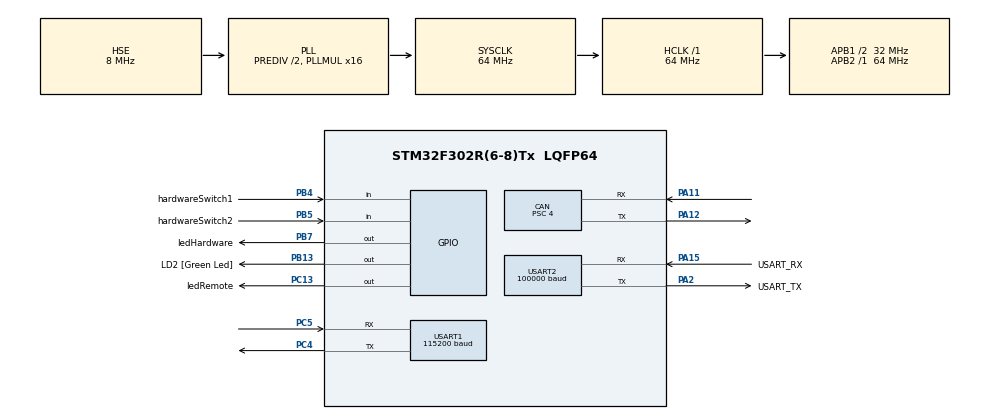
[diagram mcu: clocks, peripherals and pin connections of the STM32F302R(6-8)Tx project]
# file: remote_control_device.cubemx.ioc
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CAN.ABOM=ENABLE
CAN.AWUM=ENABLE
CAN.BS1=CAN_BS1_13TQ
CAN.BS2=CAN_BS2_2TQ
CAN.CalculateBaudRate=500000
CAN.CalculateTimeBit=2000.00
CAN.CalculateTimeQuantum=125.0
CAN.NART=ENABLE
CAN.Prescaler=4
CAN.SJW=CAN_SJW_1TQ
CAN.TXFP=ENABLE
Dma.Request0=USART1_TX
Dma.Request1=USART1_RX
Dma.Request2=USART2_RX
Dma.USART1_RX.1.Direction=DMA_PERIPH_TO_MEMORY
Dma.USART1_RX.1.Instance=DMA1_Channel5
Dma.USART1_RX.1.MemDataAlignment=DMA_MDATAALIGN_BYTE
Dma.USART1_RX.1.MemInc=DMA_MINC_ENABLE
Dma.USART1_RX.1.Mode=DMA_NORMAL
Dma.USART1_RX.1.PeriphDataAlignment=DMA_PDATAALIGN_BYTE
Dma.USART1_RX.1.PeriphInc=DMA_PINC_DISABLE
Dma.USART1_RX.1.Priority=DMA_PRIORITY_LOW
Dma.USART1_TX.0.Direction=DMA_MEMORY_TO_PERIPH
Dma.USART1_TX.0.Instance=DMA1_Channel4
Dma.USART1_TX.0.MemDataAlignment=DMA_MDATAALIGN_BYTE
Dma.USART1_TX.0.MemInc=DMA_MINC_ENABLE
Dma.USART1_TX.0.Mode=DMA_NORMAL
Dma.USART1_TX.0.PeriphDataAlignment=DMA_PDATAALIGN_BYTE
Dma.USART1_TX.0.PeriphInc=DMA_PINC_DISABLE
Dma.USART1_TX.0.Priority=DMA_PRIORITY_LOW
Dma.USART2_RX.2.Direction=DMA_PERIPH_TO_MEMORY
Dma.USART2_RX.2.Instance=DMA1_Channel6
Dma.USART2_RX.2.MemDataAlignment=DMA_MDATAALIGN_BYTE
Dma.USART2_RX.2.MemInc=DMA_MINC_ENABLE
Dma.USART2_RX.2.Mode=DMA_NORMAL
Dma.USART2_RX.2.PeriphDataAlignment=DMA_PDATAALIGN_BYTE
Dma.USART2_RX.2.PeriphInc=DMA_PINC_DISABLE
Dma.USART2_RX.2.Priority=DMA_PRIORITY_MEDIUM
FREERTOS.HEAP_NUMBER=1
FREERTOS.Tasks01=Application,24,250,startApplication,As weak,NULL,Dynamic,NULL,NULL
FREERTOS.configCHECK_FOR_STACK_OVERFLOW=2
FREERTOS.configRECORD_STACK_HIGH_ADDRESS=1
FREERTOS.configTIMER_QUEUE_LENGTH=3
FREERTOS.configTIMER_TASK_STACK_DEPTH=160
FREERTOS.configTOTAL_HEAP_SIZE=8350
IWDG.Reload=600
IWDG.Window=500
Mcu.Family=STM32F3
Mcu.Name=STM32F302R(6-8)Tx
Mcu.Package=LQFP64
NVIC.CAN_RX1_IRQn=true\:13\:0\:true\:true\:true\:3\:false\:true\:true
NVIC.CAN_SCE_IRQn=true\:13\:0\:true\:false\:true\:false\:true\:true
NVIC.DMA1_Channel4_IRQn=true\:15\:0\:true\:false\:true\:false\:false\:true
NVIC.DMA1_Channel5_IRQn=true\:15\:0\:true\:false\:true\:false\:false\:true
NVIC.DMA1_Channel6_IRQn=true\:15\:0\:true\:false\:true\:false\:false\:true
NVIC.PriorityGroup=NVIC_PRIORITYGROUP_4
NVIC.TIM1_UP_TIM16_IRQn=true\:0\:0\:false\:false\:true\:false\:false\:true
NVIC.TIM6_DAC_IRQn=true\:15\:0\:true\:false\:true\:false\:true\:true
NVIC.TimeBase=TIM1_UP_TIM16_IRQn
NVIC.TimeBaseIP=TIM1
NVIC.USART1_IRQn=true\:15\:0\:true\:false\:true\:false\:true\:true
NVIC.USART2_IRQn=true\:14\:0\:true\:false\:true\:false\:true\:true
NVIC.USB_HP_CAN_TX_IRQn=true\:13\:0\:true\:true\:true\:1\:false\:true\:true
NVIC.USB_LP_CAN_RX0_IRQn=true\:13\:0\:true\:true\:true\:2\:false\:true\:true
PA11.Mode=CAN_Activate
PA11.Signal=CAN_RX
PA12.Mode=CAN_Activate
PA12.Signal=CAN_TX
PA13.GPIO_Label=TMS
PA13.Mode=Trace_Asynchronous_SW
PA13.Signal=SYS_JTMS-SWDIO
PA14.GPIO_Label=TCK
PA14.Mode=Trace_Asynchronous_SW
PA14.Signal=SYS_JTCK-SWCLK
PA15.GPIO_Label=USART_RX
PA15.GPIO_PuPd=GPIO_NOPULL
PA15.GPIO_Speed=GPIO_SPEED_FREQ_LOW
PA15.Mode=Asynchronous
PA15.Signal=USART2_RX
PA2.GPIO_Label=USART_TX
PA2.GPIO_Mode=GPIO_MODE_AF_PP
PA2.GPIO_PuPd=GPIO_NOPULL
PA2.GPIO_Speed=GPIO_SPEED_FREQ_LOW
PA2.Mode=Asynchronous
PA2.Signal=USART2_TX
PB13.GPIO_Label=LD2 [Green Led]
PB13.Signal=GPIO_Output
PB3.GPIO_Label=SWO
PB3.Mode=Trace_Asynchronous_SW
PB3.Signal=SYS_JTDO-TRACESWO
PB4.GPIO_Label=hardwareSwitch1
PB4.GPIO_PuPd=GPIO_PULLUP
PB4.Signal=GPIO_Input
PB5.GPIO_Label=hardwareSwitch2
PB5.GPIO_PuPd=GPIO_PULLUP
PB5.Signal=GPIO_Input
PB7.GPIO_Label=ledHardware
PB7.Signal=GPIO_Output
PC13.GPIO_Label=ledRemote
PC13.Signal=GPIO_Output
PC14\ -\ OSC32_IN.Signal=RCC_OSC32_IN
PC15\ -\ OSC32_OUT.Signal=RCC_OSC32_OUT
PC4.Mode=Asynchronous
PC4.Signal=USART1_TX
PC5.Mode=Asynchronous
PC5.Signal=USART1_RX
PF0-OSC_IN.Mode=HSE-External-Clock-Source
PF0-OSC_IN.Signal=RCC_OSC_IN
PF1-OSC_OUT.Signal=RCC_OSC_OUT
ProjectManager.HeapSize=0x200
ProjectManager.StackSize=0x400
ProjectManager.TargetToolchain=Makefile
RCC.AHBFreq_Value=64000000
RCC.APB1CLKDivider=RCC_HCLK_DIV2
RCC.APB1Freq_Value=32000000
RCC.APB1TimFreq_Value=64000000
RCC.APB2Freq_Value=64000000
RCC.APB2TimFreq_Value=64000000
RCC.CortexFreq_Value=64000000
RCC.EnbaleCSS=true
RCC.HCLKFreq_Value=64000000
RCC.HSE_VALUE=8000000
RCC.HSI_VALUE=8000000
RCC.LSE_VALUE=32768
RCC.PLLM=8
RCC.PLLMUL=RCC_PLL_MUL16
RCC.PLLN=336
RCC.PLLP=RCC_PLLP_DIV4
RCC.PLLQ=7
RCC.PLLSourceVirtual=RCC_PLLSOURCE_HSE
RCC.RCC_PLLsource_Clock_Source_FROM_HSE=RCC_HSE_PREDIV_DIV2
RCC.SYSCLKFreq_VALUE=64000000
RCC.SYSCLKSourceVirtual=RCC_SYSCLKSOURCE_PLLCLK
RCC.USBFreq_Value=64000000
TIM6.Prescaler=15
USART1.BaudRate=115200
USART1.VirtualMode-Asynchronous=VM_ASYNC
USART2.BaudRate=100000
USART2.Mode=MODE_RX
USART2.Parity=PARITY_EVEN
USART2.StopBits=STOPBITS_2
USART2.SwapParam=ADVFEATURE_SWAP_DISABLE
USART2.VirtualMode-Asynchronous=VM_ASYNC
USART2.WordLength=WORDLENGTH_9B
VP_FREERTOS_VS_CMSIS_V2.Mode=CMSIS_V2
VP_IWDG_VS_IWDG.Mode=IWDG_Activate
VP_SYS_VS_tim1.Mode=TIM1
VP_TIM6_VS_ClockSourceINT.Mode=Enable_Timer
board=NUCLEO-F302R8

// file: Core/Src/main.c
/* USER CODE BEGIN Header */
/**
  ******************************************************************************
  * @file           : main.c
  * @brief          : Main program body
  ******************************************************************************
  * @attention
  *
  * <h2><center>&copy; Copyright (c) 2020 STMicroelectronics.
  * All rights reserved.</center></h2>
  *
  * This software component is licensed by ST under Ultimate Liberty license
  * SLA0044, the "License"; You may not use this file except in compliance with
  * the License. You may obtain a copy of the License at:
  *                             www.st.com/SLA0044
  *
  ******************************************************************************
  */
/* USER CODE END Header */
#include "main.h"
#include "cmsis_os.h"
#include "can.h"
#include "dma.h"
#include "iwdg.h"
#include "tim.h"
#include "usart.h"
#include "gpio.h"

void SystemClock_Config(void);
void MX_FREERTOS_Init(void);
static void MX_NVIC_Init(void);

int main(void)
{

  /* MCU Configuration--------------------------------------------------------*/

  /* Reset of all peripherals, Initializes the Flash interface and the Systick. */
  HAL_Init();

  /* Configure the system clock */
  SystemClock_Config();

  /* Initialize all configured peripherals */
  MX_GPIO_Init();
  MX_DMA_Init();
  MX_CAN_Init();
  MX_USART1_UART_Init();
  MX_USART2_UART_Init();
  MX_TIM6_Init();
  MX_IWDG_Init();

  /* Initialize interrupts */
  MX_NVIC_Init();

  /* Init scheduler */
  osKernelInitialize();  /* Call init function for freertos objects (in freertos.c) */
  MX_FREERTOS_Init();
  /* Start scheduler */
  osKernelStart();

  /* We should never get here as control is now taken by the scheduler */
  /* Infinite loop */
  while (1)
  {

  }
}

void SystemClock_Config(void)
{
  RCC_OscInitTypeDef RCC_OscInitStruct = {0};
  RCC_ClkInitTypeDef RCC_ClkInitStruct = {0};
  RCC_PeriphCLKInitTypeDef PeriphClkInit = {0};

  /** Initializes the RCC Oscillators according to the specified parameters
  * in the RCC_OscInitTypeDef structure.
  */
  RCC_OscInitStruct.OscillatorType = RCC_OSCILLATORTYPE_LSI|RCC_OSCILLATORTYPE_HSE;
  RCC_OscInitStruct.HSEState = RCC_HSE_BYPASS;
  RCC_OscInitStruct.HSEPredivValue = RCC_HSE_PREDIV_DIV2;
  RCC_OscInitStruct.HSIState = RCC_HSI_ON;
  RCC_OscInitStruct.LSIState = RCC_LSI_ON;
  RCC_OscInitStruct.PLL.PLLState = RCC_PLL_ON;
  RCC_OscInitStruct.PLL.PLLSource = RCC_PLLSOURCE_HSE;
  RCC_OscInitStruct.PLL.PLLMUL = RCC_PLL_MUL16;
  if (HAL_RCC_OscConfig(&RCC_OscInitStruct) != HAL_OK)
  {
    Error_Handler();
  }
  /** Initializes the CPU, AHB and APB buses clocks
  */
  RCC_ClkInitStruct.ClockType = RCC_CLOCKTYPE_HCLK|RCC_CLOCKTYPE_SYSCLK
                              |RCC_CLOCKTYPE_PCLK1|RCC_CLOCKTYPE_PCLK2;
  RCC_ClkInitStruct.SYSCLKSource = RCC_SYSCLKSOURCE_PLLCLK;
  RCC_ClkInitStruct.AHBCLKDivider = RCC_SYSCLK_DIV1;
  RCC_ClkInitStruct.APB1CLKDivider = RCC_HCLK_DIV2;
  RCC_ClkInitStruct.APB2CLKDivider = RCC_HCLK_DIV1;

  if (HAL_RCC_ClockConfig(&RCC_ClkInitStruct, FLASH_LATENCY_2) != HAL_OK)
  {
    Error_Handler();
  }
  PeriphClkInit.PeriphClockSelection = RCC_PERIPHCLK_USART1;
  PeriphClkInit.Usart1ClockSelection = RCC_USART1CLKSOURCE_PCLK1;
  if (HAL_RCCEx_PeriphCLKConfig(&PeriphClkInit) != HAL_OK)
  {
    Error_Handler();
  }
  /** Enables the Clock Security System
  */
  HAL_RCC_EnableCSS();
}

/**
  * @brief NVIC Configuration.
  * @retval None
  */
static void MX_NVIC_Init(void)
{
  /* USB_HP_CAN_TX_IRQn interrupt configuration */
  HAL_NVIC_SetPriority(USB_HP_CAN_TX_IRQn, 13, 0);
  HAL_NVIC_EnableIRQ(USB_HP_CAN_TX_IRQn);
  /* USB_LP_CAN_RX0_IRQn interrupt configuration */
  HAL_NVIC_SetPriority(USB_LP_CAN_RX0_IRQn, 13, 0);
  HAL_NVIC_EnableIRQ(USB_LP_CAN_RX0_IRQn);
  /* CAN_RX1_IRQn interrupt configuration */
  HAL_NVIC_SetPriority(CAN_RX1_IRQn, 13, 0);
  HAL_NVIC_EnableIRQ(CAN_RX1_IRQn);
}

 /**
  * @brief  Period elapsed callback in non blocking mode
  * @note   This function is called  when TIM1 interrupt took place, inside
  * HAL_TIM_IRQHandler(). It makes a direct call to HAL_IncTick() to increment
  * a global variable "uwTick" used as application time base.
  * @param  htim : TIM handle
  * @retval None
  */
void HAL_TIM_PeriodElapsedCallback(TIM_HandleTypeDef *htim)
{
  if (htim->Instance == TIM1) {
    HAL_IncTick();
  }
}

void Error_Handler(void)
{
}

/************************ (C) COPYRIGHT STMicroelectronics *****END OF FILE****/

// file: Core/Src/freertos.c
/* USER CODE BEGIN Header */
/**
 ******************************************************************************
 * File Name          : freertos.c
 * Description        : Code for freertos applications
 ******************************************************************************
 * @attention
 *
 * <h2><center>&copy; Copyright (c) 2020 STMicroelectronics.
 * All rights reserved.</center></h2>
 *
 * This software component is licensed by ST under Ultimate Liberty license
 * SLA0044, the "License"; You may not use this file except in compliance with
 * the License. You may obtain a copy of the License at:
 *                             www.st.com/SLA0044
 *
 ******************************************************************************
 */
/* USER CODE END Header */

#include "FreeRTOS.h"
#include "task.h"
#include "main.h"
#include "cmsis_os.h"

/* Definitions for Application */
osThreadId_t ApplicationHandle;
const osThreadAttr_t Application_attributes = {
  .name = "Application",
  .priority = (osPriority_t) osPriorityNormal,
  .stack_size = 250 * 4
};

void startApplication(void *argument);

void MX_FREERTOS_Init(void); /* (MISRA C 2004 rule 8.1) */

/* Hook prototypes */
void vApplicationStackOverflowHook(xTaskHandle xTask, signed char *pcTaskName);

/* USER CODE BEGIN 4 */
__weak void vApplicationStackOverflowHook(xTaskHandle xTask, signed char *pcTaskName)
{
    /* Run time stack overflow checking is performed if
    configCHECK_FOR_STACK_OVERFLOW is defined to 1 or 2. This hook function is
    called if a stack overflow is detected. */

  // extract for debugger
    volatile char taskName[6] = {pcTaskName[0], pcTaskName[1], pcTaskName[2],
                                 pcTaskName[3], pcTaskName[4], 0};

#ifdef DEBUG
    __asm("bkpt");
#endif

    for (;;)
    {
    };
}
/* USER CODE END 4 */

void MX_FREERTOS_Init(void) {

  /* Create the thread(s) */
  /* creation of Application */
  ApplicationHandle = osThreadNew(startApplication, NULL, &Application_attributes);

}

__weak void startApplication(void *argument)
{
  for(;;)
  {
    osDelay(1);
  }
}

/************************ (C) COPYRIGHT STMicroelectronics *****END OF FILE****/
